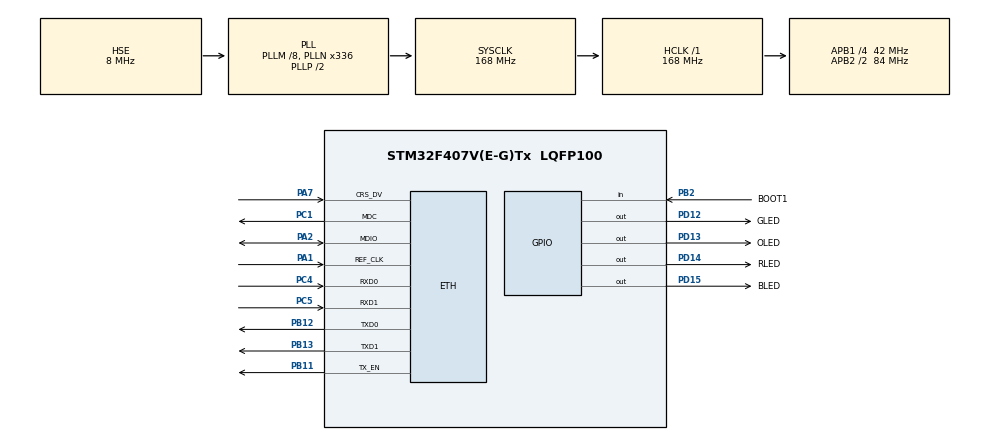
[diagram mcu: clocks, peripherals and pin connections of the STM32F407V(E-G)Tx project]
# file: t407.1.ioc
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ETH.MACAddr=00\:80\:E1\:12\:34\:56
ETH.MediaInterface=ETH_MEDIA_INTERFACE_RMII
ETH.PHY_Name_RMII=DP83848_PHY_ADDRESS
ETH.PhyAddress=1
LWIP.GATEWAY_ADDRESS=172.016.027.001
LWIP.IP_ADDRESS=172.016.027.126
LWIP.LWIP_BROADCAST_PING=1
LWIP.LWIP_DHCP=0
LWIP.LWIP_IPV6=0
LWIP.LWIP_MULTICAST_PING=1
LWIP.LWIP_TIMERS=1
LWIP.LWIP_TIMERS_CUSTOM=0
LWIP.MEMP_NUM_TCP_SEG=24
LWIP.MEM_SIZE=4000
LWIP.NETMASK_ADDRESS=255.255.255.000
LWIP.TCP_SND_BUF=2048
LWIP.Version=v2.0.3_Cube
Mcu.Family=STM32F4
Mcu.Name=STM32F407V(E-G)Tx
Mcu.Package=LQFP100
NVIC.ETH_IRQn=true\:0\:0\:false\:false\:true\:true\:true
NVIC.ETH_WKUP_IRQn=true\:0\:0\:false\:false\:true\:true\:true
NVIC.PriorityGroup=NVIC_PRIORITYGROUP_4
NVIC.TIM2_IRQn=true\:0\:0\:false\:false\:true\:true\:true
NVIC.TimeBase=TIM2_IRQn
NVIC.TimeBaseIP=TIM2
PA1.Mode=RMII
PA1.Signal=ETH_REF_CLK
PA13.GPIO_Label=SWDIO
PA13.Mode=Serial_Wire
PA13.Signal=SYS_JTMS-SWDIO
PA14.GPIO_Label=SWCLK
PA14.Mode=Serial_Wire
PA14.Signal=SYS_JTCK-SWCLK
PA2.Mode=RMII
PA2.Signal=ETH_MDIO
PA7.Mode=RMII
PA7.Signal=ETH_CRS_DV
PB11.Mode=RMII
PB11.Signal=ETH_TX_EN
PB12.Mode=RMII
PB12.Signal=ETH_TXD0
PB13.Mode=RMII
PB13.Signal=ETH_TXD1
PB2.GPIO_Label=BOOT1
PB2.GPIO_Mode=GPIO_MODE_INPUT
PB2.GPIO_PuPd=GPIO_NOPULL
PB2.Signal=GPIO_Input
PC1.Mode=RMII
PC1.Signal=ETH_MDC
PC4.Mode=RMII
PC4.Signal=ETH_RXD0
PC5.Mode=RMII
PC5.Signal=ETH_RXD1
PD12.GPIO_Label=GLED
PD12.GPIO_PuPd=GPIO_NOPULL
PD12.GPIO_Speed=GPIO_SPEED_FREQ_LOW
PD12.Signal=GPIO_Output
PD13.GPIO_Label=OLED
PD13.GPIO_PuPd=GPIO_NOPULL
PD13.GPIO_Speed=GPIO_SPEED_FREQ_LOW
PD13.Signal=GPIO_Output
PD14.GPIO_Label=RLED
PD14.GPIO_PuPd=GPIO_NOPULL
PD14.GPIO_Speed=GPIO_SPEED_FREQ_LOW
PD14.Signal=GPIO_Output
PD15.GPIO_Label=BLED
PD15.GPIO_PuPd=GPIO_NOPULL
PD15.GPIO_Speed=GPIO_SPEED_FREQ_LOW
PD15.Signal=GPIO_Output
PH0-OSC_IN.GPIO_Label=PH0-OSC_IN
PH0-OSC_IN.Mode=HSE-External-Oscillator
PH0-OSC_IN.Signal=RCC_OSC_IN
PH1-OSC_OUT.GPIO_Label=PH1-OSC_OUT
PH1-OSC_OUT.Mode=HSE-External-Oscillator
PH1-OSC_OUT.Signal=RCC_OSC_OUT
ProjectManager.HeapSize=0x4000
ProjectManager.StackSize=0x4000
ProjectManager.TargetToolchain=Makefile
RCC.48MHZClocksFreq_Value=48000000
RCC.AHBFreq_Value=168000000
RCC.APB1CLKDivider=RCC_HCLK_DIV4
RCC.APB1Freq_Value=42000000
RCC.APB1TimFreq_Value=84000000
RCC.APB2CLKDivider=RCC_HCLK_DIV2
RCC.APB2Freq_Value=84000000
RCC.APB2TimFreq_Value=168000000
RCC.CortexFreq_Value=168000000
RCC.HCLKFreq_Value=168000000
RCC.HSE_VALUE=8000000
RCC.HSI_VALUE=16000000
RCC.LSE_VALUE=32768
RCC.PLLM=8
RCC.PLLN=336
RCC.PLLQ=7
RCC.PLLSourceVirtual=RCC_PLLSOURCE_HSE
RCC.SYSCLKFreq_VALUE=168000000
RCC.SYSCLKSource=RCC_SYSCLKSOURCE_PLLCLK
RCC.VCOOutputFreq_Value=336000000
VP_LWIP_VS_Enabled.Mode=Enabled
VP_SYS_VS_tim2.Mode=TIM2
board=STM32F407G-DISC1

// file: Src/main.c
/* USER CODE BEGIN Header */
/**
  ******************************************************************************
  * @file           : main.c
  * @brief          : Main program body
  ******************************************************************************
  * @attention
  *
  * <h2><center>&copy; Copyright (c) 2019 STMicroelectronics.
  * All rights reserved.</center></h2>
  *
  * This software component is licensed by ST under Ultimate Liberty license
  * SLA0044, the "License"; You may not use this file except in compliance with
  * the License. You may obtain a copy of the License at:
  *                             www.st.com/SLA0044
  *
  ******************************************************************************
  */
/* USER CODE END Header */

#include "main.h"
#include "lwip.h"
#include "gpio.h"

/* USER CODE BEGIN Includes */
#include "leds.h"
/* USER CODE END Includes */

/* USER CODE BEGIN PV */
extern struct netif gnetif;
/* USER CODE END PV */

void SystemClock_Config(void);

int main(void)
{

  /* MCU Configuration--------------------------------------------------------*/

  /* Reset of all peripherals, Initializes the Flash interface and the Systick. */
  HAL_Init();

  /* Configure the system clock */
  SystemClock_Config();

  /* Initialize all configured peripherals */
  MX_GPIO_Init();
  MX_LWIP_Init();

  /* Infinite loop */
  while (1)
  {

    /* USER CODE BEGIN 3 */
    ethernetif_input(&gnetif);
    sys_check_timeouts();
    oled_toggle();
  }
  /* USER CODE END 3 */
}

void SystemClock_Config(void)
{
  RCC_OscInitTypeDef RCC_OscInitStruct = {0};
  RCC_ClkInitTypeDef RCC_ClkInitStruct = {0};

  /** Configure the main internal regulator output voltage
  */
  __HAL_RCC_PWR_CLK_ENABLE();
  __HAL_PWR_VOLTAGESCALING_CONFIG(PWR_REGULATOR_VOLTAGE_SCALE1);
  /** Initializes the CPU, AHB and APB busses clocks
  */
  RCC_OscInitStruct.OscillatorType = RCC_OSCILLATORTYPE_HSE;
  RCC_OscInitStruct.HSEState = RCC_HSE_ON;
  RCC_OscInitStruct.PLL.PLLState = RCC_PLL_ON;
  RCC_OscInitStruct.PLL.PLLSource = RCC_PLLSOURCE_HSE;
  RCC_OscInitStruct.PLL.PLLM = 8;
  RCC_OscInitStruct.PLL.PLLN = 336;
  RCC_OscInitStruct.PLL.PLLP = RCC_PLLP_DIV2;
  RCC_OscInitStruct.PLL.PLLQ = 7;
  if (HAL_RCC_OscConfig(&RCC_OscInitStruct) != HAL_OK)
  {
    Error_Handler();
  }
  /** Initializes the CPU, AHB and APB busses clocks
  */
  RCC_ClkInitStruct.ClockType = RCC_CLOCKTYPE_HCLK|RCC_CLOCKTYPE_SYSCLK
                              |RCC_CLOCKTYPE_PCLK1|RCC_CLOCKTYPE_PCLK2;
  RCC_ClkInitStruct.SYSCLKSource = RCC_SYSCLKSOURCE_PLLCLK;
  RCC_ClkInitStruct.AHBCLKDivider = RCC_SYSCLK_DIV1;
  RCC_ClkInitStruct.APB1CLKDivider = RCC_HCLK_DIV4;
  RCC_ClkInitStruct.APB2CLKDivider = RCC_HCLK_DIV2;

  if (HAL_RCC_ClockConfig(&RCC_ClkInitStruct, FLASH_LATENCY_5) != HAL_OK)
  {
    Error_Handler();
  }
}

void HAL_TIM_PeriodElapsedCallback(TIM_HandleTypeDef *htim)
{
  if (htim->Instance == TIM2) {
    HAL_IncTick();
  }
}

void Error_Handler(void)
{
}

/************************ (C) COPYRIGHT STMicroelectronics *****END OF FILE****/
